# sifive_qemu_sifive_s51 register map
File version: 0.1
Registers are 32-bit, read-write, no defined reset value unless marked. A register's access mark holds for its fields unless they carry their own. Offsets are from the block's base; [hi:lo] are bit positions.

## sifive_fe310_g000_prci_0 — From sifive,fe310-g000,prci,mem peripheral generator
Base 0x10008000
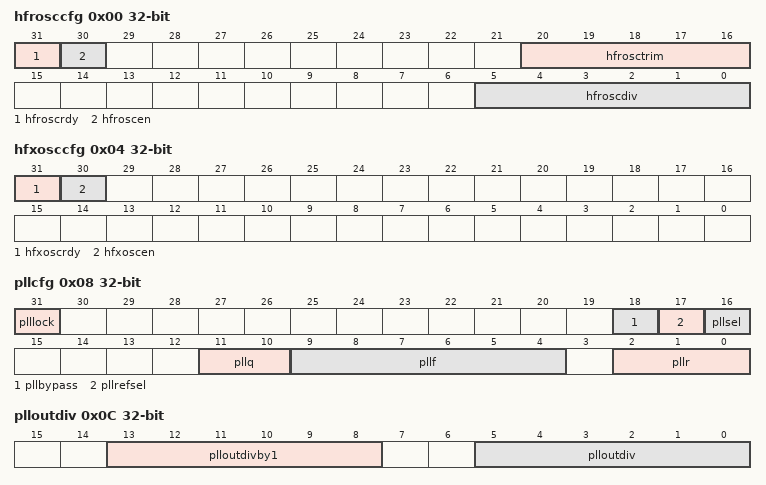
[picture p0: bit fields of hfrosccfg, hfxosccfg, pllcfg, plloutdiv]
0x00 hfrosccfg — Ring Oscillator Configuration and Status
  [31] hfroscrdy ro — Ring Oscillator Ready
  [30] hfroscen — Ring Oscillator Enable
  [20:16] hfrosctrim — Ring Oscillator Trim Register
  [5:0] hfroscdiv — Ring Oscillator Divider Register
0x04 hfxosccfg — Crystal Oscillator Configuration and Status
  [31] hfxoscrdy ro — Crystal Oscillator Ready
  [30] hfxoscen — Crystal Oscillator Enable
0x08 pllcfg — PLL Configuration and Status
  [31] plllock ro
  [18] pllbypass
  [17] pllrefsel — PLL Reference Select
  [16] pllsel — PLL Select
  [11:10] pllq — PLL Q Value
  [9:4] pllf — PLL F Value
  [2:0] pllr — PLL R Value
0x0C plloutdiv — PLL Final Divide Configuration
  [13:8] plloutdivby1 — PLL Final Divide By 1
  [5:0] plloutdiv — PLL Final Divider Value
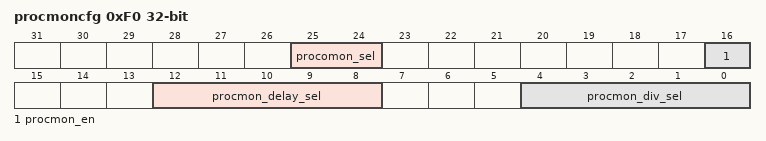
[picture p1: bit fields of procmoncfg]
0xF0 procmoncfg — Process Monitor Configuration and Status
  [25:24] procomon_sel — Process Monitor Select
  [16] procmon_en — Process Monitor Enable
  [12:8] procmon_delay_sel — Process Monitor Delay Selector
  [4:0] procmon_div_sel — Proccess Monitor Divider

## sifive_gpio0_0 — From sifive,gpio0,control peripheral generator
Base 0x10012000
0x00 input_val — Pin value
0x04 input_en — Pin input enable
0x08 output_en — Pin output enable
0x0C output_val — Output value
0x10 pue — Internal pull-up enable
0x14 ds — Pin drive strength
0x18 rise_ie — Rise interrupt enable
0x1C rise_ip — Rise interrupt pending
0x20 fall_ie — Fall interrupt enable
0x24 fall_ip — Fall interrupt pending
0x28 high_ie — High interrupt enable
0x2C high_ip — High interrupt pending
0x30 low_ie — Low interrupt enable
0x34 low_ip — Low interrupt pending
0x38 iof_en — I/O function enable
0x3C iof_sel — I/O function select
0x40 out_xor — Output XOR (invert)

## sifive_uart0_0 — From sifive,uart0,control peripheral generator
Base 0x10013000
Same registers: sifive_uart0_1 0x10023000
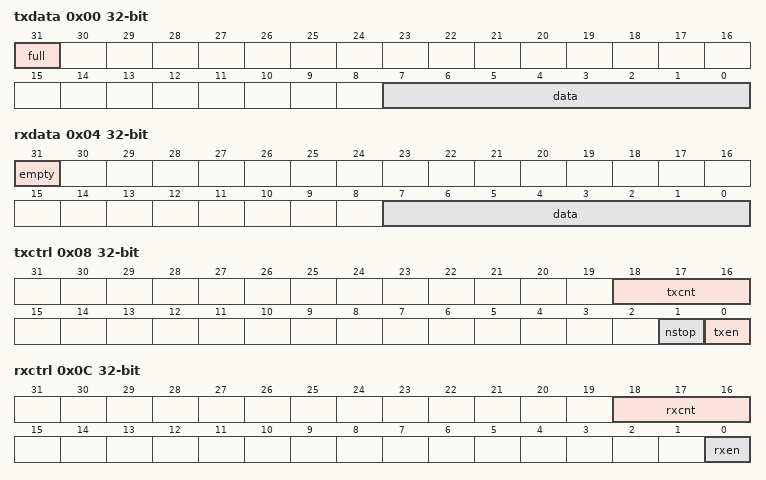
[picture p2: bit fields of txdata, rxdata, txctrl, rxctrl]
0x00 txdata — Transmit data register
  [31] full ro — Transmit FIFO full
  [7:0] data — Transmit data
0x04 rxdata — Receive data register
  [31] empty ro — Receive FIFO empty
  [7:0] data ro — Received data
0x08 txctrl — Transmit control register
  [18:16] txcnt — Transmit watermark level
  [1] nstop — Number of stop bits
  [0] txen — Transmit enable
0x0C rxctrl — Receive control register
  [18:16] rxcnt — Receive watermark level
  [0] rxen — Receive enable
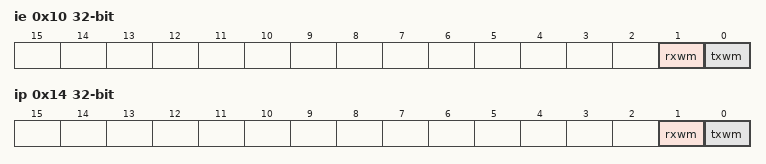
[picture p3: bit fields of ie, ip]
0x10 ie — UART interrupt enable
  [1] rxwm — Receive watermark interrupt enable
  [0] txwm — Transmit watermark interrupt enable
0x14 ip — UART interrupt pending
  [1] rxwm ro — Receive watermark interrupt pending
  [0] txwm ro — Transmit watermark interrupt pending
0x18 div — Baud rate divisor
  [15:0] div — Baud rate divisor.

## sifive_spi0_0 — From sifive,spi0,control peripheral generator
Base 0x10014000
0x00 sckdiv — Serial clock divisor
  [11:0] div — Divisor for serial clock.
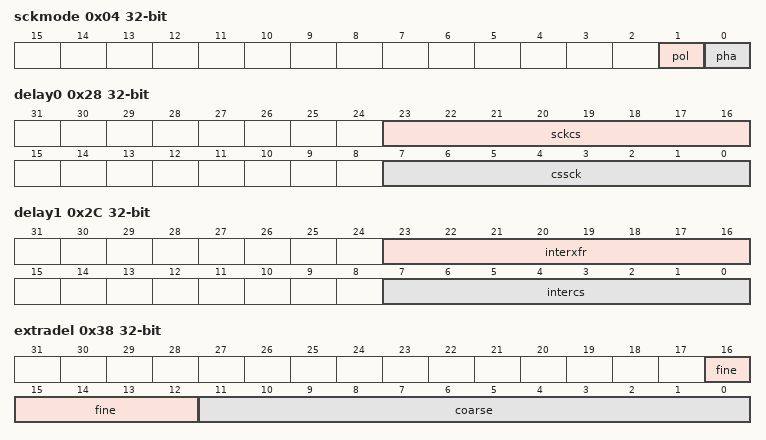
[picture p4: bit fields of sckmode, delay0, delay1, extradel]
0x04 sckmode — Serial clock mode
  [1] pol — Serial clock polarity
  [0] pha — Serial clock phase
0x10 csid — Chip select ID
  [31:0] csid — Chip select ID.
0x14 csdef — Chip select default
  [31:0] csdef — Chip select default value. Reset to all-1s.
0x18 csmode — Chip select mode
  [1:0] mode
0x28 delay0 — Delay control 0
  [23:16] sckcs — SCK to CS Delay
  [7:0] cssck — CS to SCK Delay
0x2C delay1 — Delay control 1
  [23:16] interxfr — Maximum interframe delay
  [7:0] intercs — Minimum CS inactive time
0x38 extradel — SPI extra sampling delay to increase the SPI frequency
  [16:12] fine — Fine grain sample delay (multiples of process-specific buffer delay)
  [11:0] coarse — Coarse grain sample delay (multiples of system clocks)
0x3C sampledel — Number of delay stages from slave to the SPI controller
  [4:0] sd — Number of delay stages from slave to SPI controller
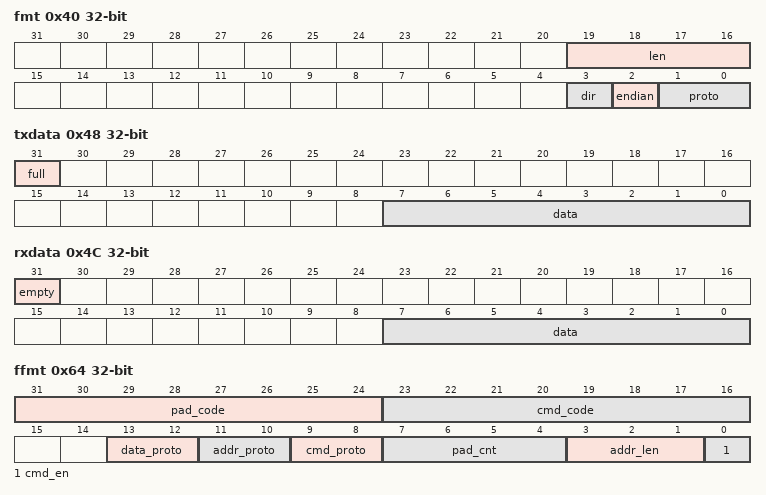
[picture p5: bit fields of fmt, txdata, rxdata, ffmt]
0x40 fmt — Frame format
  [19:16] len — Number of bits per frame
  [3] dir — SPI I/O direction. This is reset to 1 for flash-enabled SPI controllers, 0 otherwise.
  [2] endian — SPI endianness
  [1:0] proto — SPI protocol
0x48 txdata — Tx FIFO Data
  [31] full ro — FIFO full flag
  [7:0] data — Transmit data
0x4C rxdata — Rx FIFO data
  [31] empty — FIFO empty flag
  [7:0] data ro — Received data
0x50 txmark — Tx FIFO watermark
  [2:0] txmark — Transmit watermark. The reset value is 1 for flash-enabled controllers, 0 otherwise.
0x54 rxmark — Rx FIFO watermark
  [2:0] rxmark — Receive watermark
0x60 fctrl — SPI flash interface control
  [0] en — SPI Flash Mode Select
0x64 ffmt — SPI flash instruction format
  [31:24] pad_code — First 8 bits to transmit during dummy cycles
  [23:16] cmd_code — Value of command byte
  [13:12] data_proto — Protocol for receiving data bytes
  [11:10] addr_proto — Protocol for transmitting address and padding
  [9:8] cmd_proto — Protocol for transmitting command
  [7:4] pad_cnt — Number of dummy cycles
  [3:1] addr_len — Number of address bytes (0 to 4)
  [0] cmd_en — Enable sending of command
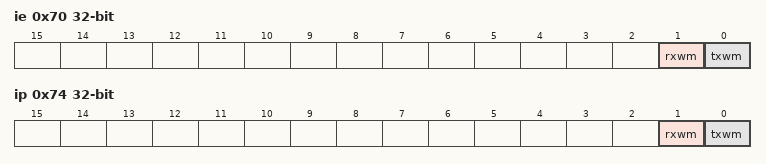
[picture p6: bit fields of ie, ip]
0x70 ie — SPI interrupt enable
  [1] rxwm — Receive watermark enable
  [0] txwm — Transmit watermark enable
0x74 ip — SPI interrupt pending
  [1] rxwm ro — Receive watermark pending
  [0] txwm ro — Transmit watermark pending
